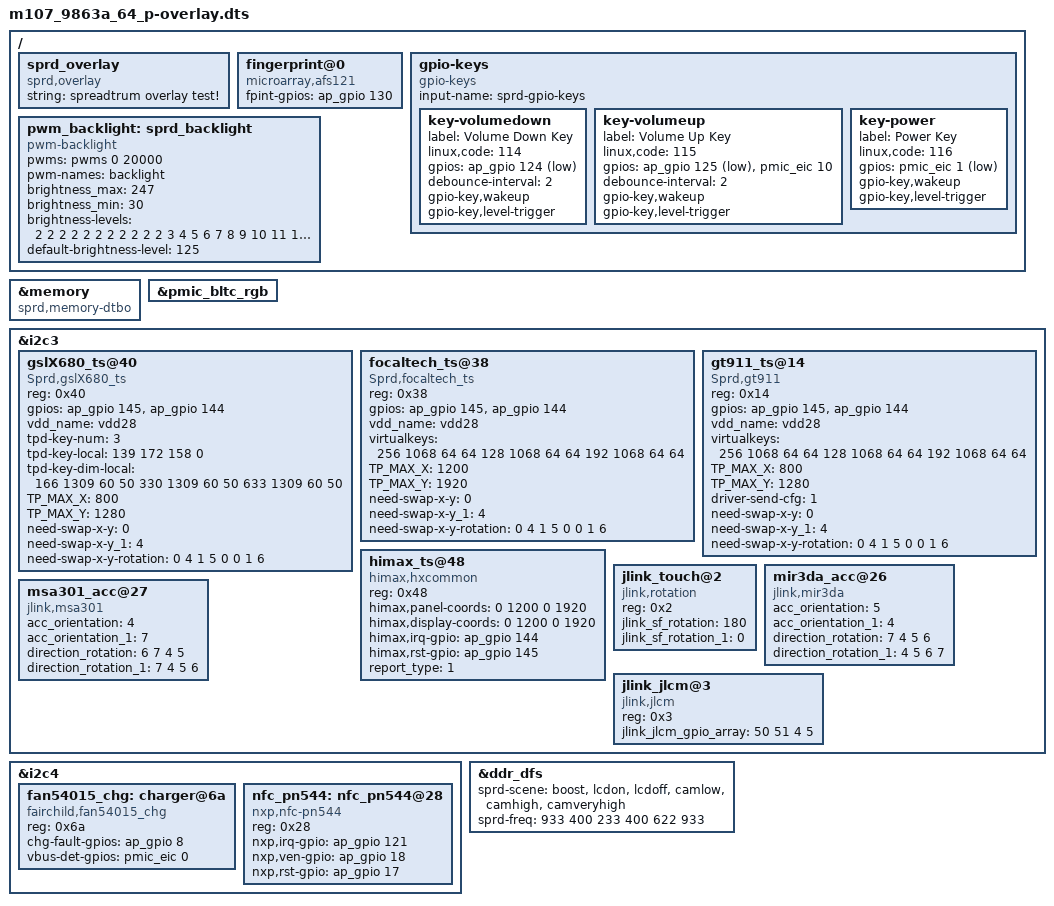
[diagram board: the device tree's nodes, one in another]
/*
 * Spreadtrum sharkl3 sp9863a board DTS file
 *
 * Copyright (C) 2018, Spreadtrum Communications Inc.
 *
 * This file is licensed under a dual GPLv2 or X11 license.
 */
/dts-v1/;
/plugin/;

/ {
	/*
	* When create a new node, we should use the key word __overlay__,
	* otherwise u-boot can not analyze it.
	*/

	fragment {
		target-path = "/";
		__overlay__ {
			sprd_overlay {
				compatible = "sprd,overlay";
				string = "spreadtrum overlay test!";
			};

			fingerprint@0 {
				compatible = "microarray,afs121";
				fpint-gpios = <&ap_gpio 130 0>;
			};

			/*
			flash_lcd: flash-lcd {
				compatible = "sprd,lcd-flash";
				sprd,dispc = <&dispc0>;
				sprd,backlight = <&pwm_backlight>;
				status = "okay";
			};
			flash_sink: flash-sink {
				compatible = "sprd,sc2721-flash";
				flash-chip-en-gpios = <&ap_gpio 133 0>;
				status = "okay";
			};
			*/

			gpio-keys {
				compatible = "gpio-keys";
				input-name = "sprd-gpio-keys";
				status = "okay";

				key-volumedown {
					label = "Volume Down Key";
					linux,code = <114>;
					gpios = <&ap_gpio 124 1>;
					debounce-interval = <2>;
					gpio-key,wakeup;
					gpio-key,level-trigger;
				};

				key-volumeup {
					label = "Volume Up Key";
					linux,code = <115>;
					gpios = <&ap_gpio 125 1 
						&pmic_eic 10 0>;
					debounce-interval = <2>;
					gpio-key,wakeup;
					gpio-key,level-trigger;
				};

				key-power {
					label = "Power Key";
					linux,code = <116>;
					gpios = <&pmic_eic 1 1>;
					gpio-key,wakeup;
					gpio-key,level-trigger;
				};
			};

			pwm_backlight: sprd_backlight {
				compatible = "pwm-backlight";
				pwms = <&pwms 0 20000>;
				pwm-names = "backlight";
				brightness_max = <247>;
				brightness_min = <30>;
				brightness-levels = <
						  2   2   2   2   2   2   2   2
					  2   2   2   3   4   5   6   7   8   9
					 10  11  12  13  14  15  16  17  18  19
					 20  21  22  23  24  25  26  27  28  29
					 30  31  32  33  34  35  36  37  38  39
					 40  41  42  43  44  45  46  47  48  49
					 50  51  52  53  54  55  56  57  58  59
					 60  61  62  63  64  65  66  67  68  69
					 70  71  72  73  74  75  76  77  78  79
					 80  81  82  83  84  85  86  87  88  89
					 90  91  92  93  94  95  96  97  98  99
					100 101 102 103 104 105 106 107 108 109
					110 111 112 113 114 115 116 117 118 119
					120 121 122 123 124 125 126 127 128 129
					130 131 132 133 134 135 136 137 138 139
					140 141 142 143 144 145 146 147 148 149
					150 151 152 153 154 155 156 157 158 159
					160 161 162 163 164 165 166 167 168 169
					170 171 172 173 174 175 176 177 178 179
					180 181 182 183 184 185 186 187 188 189
					190 191 192 193 194 195 196 197 198 199
					200 201 202 203 204 205 206 207 208 209
					210 211 212 213 214 215 216 217 218 219
					220 221 222 223 224 225 226 227 228 229
					230 231 232 233 234 235 236 237 238 239
					240 241 242 243 244 245 246 247
					>;
				default-brightness-level = <125>;
			};
		};
	};
};

/*
 * Sample code. Google strongly recommends you do not use fragment@x and
 * syntax __overlay__, and instead use the reference syntax
 */
&memory {
	compatible = "sprd,memory-dtbo";
};

&pmic_bltc_rgb {
	status = "okay";
};

&i2c3 {
	status = "okay";

	/*
	adaptive-touchscreen@38 {
		compatible = "adaptive-touchscreen";
		reg = <0x38>;
		gpios = <&ap_gpio 145 0
			&ap_gpio 144 0>;
		controller = "focaltech,FT5436";
		virtualkeys = <580 60 1320 60 45
			172 360 1320 60 45
			158 600 1320 60 45>;
		private-data {
			a8 = /bits/ 8 <0x5a>;
		};
	};
	*/
     gslX680_ts@40{
        compatible = "Sprd,gslX680_ts";
        reg = <0x40>;
		gpios = <&ap_gpio 145 0
			&ap_gpio 144 0>;
        vdd_name = "vdd28";
	tpd-key-num = <3>;
	tpd-key-local = <139 172 158 0>;
        tpd-key-dim-local  = <166 1309 60 50 330 1309 60 50 633 1309 60 50>;
        TP_MAX_X = <800>;
        TP_MAX_Y = <1280>;
	need-swap-x-y = <0>;
	need-swap-x-y_1 = <4>;
	need-swap-x-y-rotation = <0 4   1 5   0 0   1 6>;
     };
    focaltech_ts@38{
        compatible = "Sprd,focaltech_ts";
        reg = <0x38>;
		gpios = <&ap_gpio 145 0
			&ap_gpio 144 0>;
        vdd_name = "vdd28";
        virtualkeys = <256 1068 64 64
            128 1068 64 64
            192 1068 64 64>;

        TP_MAX_X = <1200>;
        TP_MAX_Y = <1920>;
	need-swap-x-y = <0>;
	need-swap-x-y_1 = <4>;
	need-swap-x-y-rotation = <0 4   1 5   0 0   1 6>;
     };
    gt911_ts@14{
        compatible = "Sprd,gt911";
        reg = <0x14>;
		gpios = <&ap_gpio 145 0
			&ap_gpio 144 0>;
        vdd_name = "vdd28";
        virtualkeys = <256 1068 64 64
            128 1068 64 64
            192 1068 64 64>;
        TP_MAX_X = <800>;
        TP_MAX_Y = <1280>;
	driver-send-cfg = <1>;
	need-swap-x-y = <0>;
	need-swap-x-y_1 = <4>;
	need-swap-x-y-rotation = <0 4   1 5   0 0   1 6>;
     };
    himax_ts@48 {
	compatible = "himax,hxcommon";
	reg = <0x48>;
	/*interrupt-parent = <&tlmm>;*/
	/*interrupts = <125 0x2008>;*/
	/*vdd-supply = <&pm8994_l14>;*/
	/*avdd-supply = <&pm8994_l22>;*/
	/*pinctrl-names = "pmx_ts_active", "pmx_ts_suspend";*/
	/*pinctrl-0 = <&ts_active>;*/
	/*pinctrl-1 = <&ts_suspend>;*/
	himax,panel-coords = <0 1200 0 1920>;
	himax,display-coords = <0 1200 0 1920>;
	himax,irq-gpio = <&ap_gpio 144 0>;
	himax,rst-gpio = <&ap_gpio 145 0>;
	report_type = <1>;
     };
     jlink_touch@2{
        compatible = "jlink,rotation";
        reg = <0x2>;
	jlink_sf_rotation = <180>;
	jlink_sf_rotation_1 = <0>;
     };

    mir3da_acc@26{
        compatible = "jlink,mir3da";
        acc_orientation = <5>;
        acc_orientation_1 = <4>;
	direction_rotation = <7 4 5 6>;
	direction_rotation_1 = <4 5 6 7>;
    };
    msa301_acc@27{
        compatible = "jlink,msa301";
        acc_orientation = <4>;
        acc_orientation_1 = <7>;
	direction_rotation = <6 7 4 5>;
	direction_rotation_1 = <7 4 5 6>;
    };
     jlink_jlcm@3{
        compatible = "jlink,jlcm";
        reg = <0x3>;
	jlink_jlcm_gpio_array = <50 51 4 5>; //0: reset pin, 1: pwr pin, 2:avdd, 3:avee ...
     };


};

&i2c4 {
	fan54015_chg: charger@6a {
		compatible = "fairchild,fan54015_chg";
		reg = <0x6a>;
		chg-fault-gpios = <&ap_gpio 8 0>;
		vbus-det-gpios = <&pmic_eic 0 0>;
	};
	nfc_pn544: nfc_pn544@28 {
		compatible = "nxp,nfc-pn544";
		reg = <0x28>;
		nxp,irq-gpio = <&ap_gpio 121 0>;
		nxp,ven-gpio = <&ap_gpio 18 0>;
		//interrupt-parent = <&d_gpio_gpio>;
		//interrupts = <229 0>;
		interrupt-names = "nfc_irq";
		nxp,rst-gpio = <&ap_gpio 17 0>;
       };   
};

&ddr_dfs {
	sprd-scene = "boost", "lcdon", "lcdoff", "camlow",
			"camhigh", "camveryhigh";
	sprd-freq = <933 400 233 400 622 933>;
};
